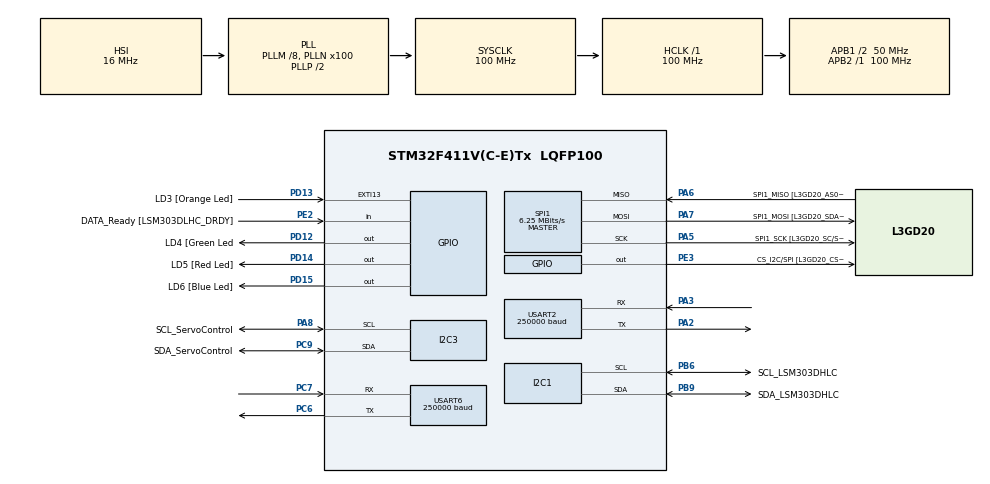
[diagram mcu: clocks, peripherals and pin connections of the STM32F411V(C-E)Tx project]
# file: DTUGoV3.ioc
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Dma.Request0=USART6_RX
Dma.Request1=USART6_TX
Dma.USART6_RX.0.Direction=DMA_PERIPH_TO_MEMORY
Dma.USART6_RX.0.FIFOMode=DMA_FIFOMODE_DISABLE
Dma.USART6_RX.0.Instance=DMA2_Stream1
Dma.USART6_RX.0.MemDataAlignment=DMA_MDATAALIGN_BYTE
Dma.USART6_RX.0.MemInc=DMA_MINC_ENABLE
Dma.USART6_RX.0.Mode=DMA_CIRCULAR
Dma.USART6_RX.0.PeriphDataAlignment=DMA_PDATAALIGN_BYTE
Dma.USART6_RX.0.PeriphInc=DMA_PINC_DISABLE
Dma.USART6_RX.0.Priority=DMA_PRIORITY_LOW
Dma.USART6_TX.1.Direction=DMA_MEMORY_TO_PERIPH
Dma.USART6_TX.1.FIFOMode=DMA_FIFOMODE_DISABLE
Dma.USART6_TX.1.Instance=DMA2_Stream6
Dma.USART6_TX.1.MemDataAlignment=DMA_MDATAALIGN_BYTE
Dma.USART6_TX.1.MemInc=DMA_MINC_ENABLE
Dma.USART6_TX.1.Mode=DMA_NORMAL
Dma.USART6_TX.1.PeriphDataAlignment=DMA_PDATAALIGN_BYTE
Dma.USART6_TX.1.PeriphInc=DMA_PINC_DISABLE
Dma.USART6_TX.1.Priority=DMA_PRIORITY_LOW
FREERTOS.Mutexes01=cmdMutex,Dynamic,NULL,Available;imuMutex,Dynamic,NULL,Available;batteryMutex,Dynamic,NULL,Available
FREERTOS.Tasks01=controlTask,48,256,StartControlTask,Default,NULL,Dynamic,NULL,NULL;imuTask,8,256,StartIMUTask,Default,NULL,Dynamic,NULL,NULL;rxCommTask,40,128,StartRxCommTask,Default,NULL,Dynamic,NULL,NULL;txCommTask,24,128,StartTxCommTask,Default,NULL,Dynamic,NULL,NULL;batteryTask,9,256,StartBatteryTask,Default,NULL,Dynamic,NULL,NULL
FREERTOS.configENABLE_FPU=1
I2C1.I2C_Mode=I2C_Fast
Mcu.Family=STM32F4
Mcu.Name=STM32F411V(C-E)Tx
Mcu.Package=LQFP100
NVIC.DMA2_Stream1_IRQn=true\:5\:0\:false\:false\:true\:true\:false\:true\:true
NVIC.DMA2_Stream6_IRQn=true\:5\:0\:false\:false\:true\:true\:false\:true\:true
NVIC.PriorityGroup=NVIC_PRIORITYGROUP_4
NVIC.TIM2_IRQn=true\:15\:0\:false\:false\:true\:false\:false\:true\:true
NVIC.TimeBase=TIM2_IRQn
NVIC.TimeBaseIP=TIM2
NVIC.USART6_IRQn=true\:5\:0\:false\:false\:true\:true\:true\:true\:true
PA13.Mode=Serial_Wire
PA13.Signal=SYS_JTMS-SWDIO
PA14.Mode=Serial_Wire
PA14.Signal=SYS_JTCK-SWCLK
PA2.Mode=Asynchronous
PA2.Signal=USART2_TX
PA3.Mode=Asynchronous
PA3.Signal=USART2_RX
PA5.GPIO_Label=SPI1_SCK [L3GD20_SC/SPC]
PA5.Mode=Full_Duplex_Master
PA5.Signal=SPI1_SCK
PA6.GPIO_Label=SPI1_MISO [L3GD20_AS0/SDO]
PA6.Mode=Full_Duplex_Master
PA6.Signal=SPI1_MISO
PA7.GPIO_Label=SPI1_MOSI [L3GD20_SDA/SDI/SDO]
PA7.Mode=Full_Duplex_Master
PA7.Signal=SPI1_MOSI
PA8.GPIO_Label=SCL_ServoControl
PA8.Mode=I2C
PA8.Signal=I2C3_SCL
PB6.GPIO_Label=SCL_LSM303DHLC
PB6.Mode=I2C
PB6.Signal=I2C1_SCL
PB9.GPIO_Label=SDA_LSM303DHLC
PB9.Mode=I2C
PB9.Signal=I2C1_SDA
PC6.Mode=Asynchronous
PC6.Signal=USART6_TX
PC7.Mode=Asynchronous
PC7.Signal=USART6_RX
PC9.GPIO_Label=SDA_ServoControl
PC9.Mode=I2C
PC9.Signal=I2C3_SDA
PD12.GPIO_Label=LD4 [Green Led
PD12.Signal=GPIO_Output
PD13.GPIO_Label=LD3 [Orange Led]
PD13.Signal=GPXTI13
PD14.GPIO_Label=LD5 [Red Led]
PD14.Signal=GPIO_Output
PD15.GPIO_Label=LD6 [Blue Led]
PD15.Signal=GPIO_Output
PE2.GPIO_Label=DATA_Ready [LSM303DLHC_DRDY]
PE2.Signal=GPIO_Input
PE3.GPIO_Label=CS_I2C/SPI [L3GD20_CS_I2C/SPI]
PE3.GPIO_Speed=GPIO_SPEED_FREQ_VERY_HIGH
PE3.PinState=GPIO_PIN_SET
PE3.Signal=GPIO_Output
PH0\ -\ OSC_IN.Mode=HSE-External-Oscillator
PH0\ -\ OSC_IN.Signal=RCC_OSC_IN
PH1\ -\ OSC_OUT.Mode=HSE-External-Oscillator
PH1\ -\ OSC_OUT.Signal=RCC_OSC_OUT
ProjectManager.HeapSize=0x200
ProjectManager.StackSize=0x400
ProjectManager.TargetToolchain=STM32CubeIDE
RCC.48MHZClocksFreq_Value=50000000
RCC.AHBFreq_Value=100000000
RCC.APB1CLKDivider=RCC_HCLK_DIV2
RCC.APB1Freq_Value=50000000
RCC.APB1TimFreq_Value=100000000
RCC.APB2Freq_Value=100000000
RCC.APB2TimFreq_Value=100000000
RCC.CortexFreq_Value=100000000
RCC.HCLKFreq_Value=100000000
RCC.HSE_VALUE=8000000
RCC.HSI_VALUE=16000000
RCC.LSE_VALUE=32768
RCC.PLLM=8
RCC.PLLN=100
RCC.SYSCLKFreq_VALUE=100000000
RCC.SYSCLKSource=RCC_SYSCLKSOURCE_PLLCLK
RCC.VCOOutputFreq_Value=200000000
SPI1.BaudRatePrescaler=SPI_BAUDRATEPRESCALER_16
SPI1.CLKPhase=SPI_PHASE_1EDGE
SPI1.CLKPolarity=SPI_POLARITY_LOW
SPI1.CalculateBaudRate=6.25 MBits/s
SPI1.Direction=SPI_DIRECTION_2LINES
SPI1.Mode=SPI_MODE_MASTER
SPI1.VirtualType=VM_MASTER
USART2.BaudRate=250000
USART2.VirtualMode=VM_ASYNC
USART6.BaudRate=250000
USART6.VirtualMode=VM_ASYNC
VP_FREERTOS_VS_CMSIS_V2.Mode=CMSIS_V2
VP_SYS_VS_tim2.Mode=TIM2
board=custom

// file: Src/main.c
/* USER CODE BEGIN Header */
/**
  ******************************************************************************
  * @file           : main.c
  * @brief          : Main program body
  ******************************************************************************
  * @attention
  *
  * Copyright (c) 2026 STMicroelectronics.
  * All rights reserved.
  *
  * This software is licensed under terms that can be found in the LICENSE file
  * in the root directory of this software component.
  * If no LICENSE file comes with this software, it is provided AS-IS.
  *
  ******************************************************************************
  */
/* USER CODE END Header */
#include "main.h"
#include "cmsis_os.h"

/* USER CODE BEGIN Includes */
#include "uart.h"
#include "freeRtosUser.h"
/* USER CODE END Includes */

I2C_HandleTypeDef hi2c1;
I2C_HandleTypeDef hi2c3;

SPI_HandleTypeDef hspi1;

UART_HandleTypeDef huart2;
UART_HandleTypeDef huart6;
DMA_HandleTypeDef hdma_usart6_rx;
DMA_HandleTypeDef hdma_usart6_tx;

void SystemClock_Config(void);
static void MX_GPIO_Init(void);
static void MX_DMA_Init(void);
static void MX_I2C1_Init(void);
static void MX_I2C3_Init(void);
static void MX_SPI1_Init(void);
static void MX_USART2_UART_Init(void);
static void MX_USART6_UART_Init(void);

int main(void)
{

  /* MCU Configuration--------------------------------------------------------*/

  /* Reset of all peripherals, Initializes the Flash interface and the Systick. */
  HAL_Init();

  /* Configure the system clock */
  SystemClock_Config();

  /* Initialize all configured peripherals */
  MX_GPIO_Init();
  MX_DMA_Init();
  MX_I2C1_Init();
  MX_I2C3_Init();
  MX_SPI1_Init();
  MX_USART2_UART_Init();
  MX_USART6_UART_Init();

  /* We should never get here as control is now taken by the scheduler */

  /* Infinite loop */
  /* USER CODE BEGIN WHILE */
  osKernelInitialize();
  MX_FREERTOS_Init();
  osKernelStart();

  while (1)
  {
    /* USER CODE END WHILE */

  }
}

void SystemClock_Config(void)
{
  RCC_OscInitTypeDef RCC_OscInitStruct = {0};
  RCC_ClkInitTypeDef RCC_ClkInitStruct = {0};

  /** Configure the main internal regulator output voltage
  */
  __HAL_RCC_PWR_CLK_ENABLE();
  __HAL_PWR_VOLTAGESCALING_CONFIG(PWR_REGULATOR_VOLTAGE_SCALE1);

  /** Initializes the RCC Oscillators according to the specified parameters
  * in the RCC_OscInitTypeDef structure.
  */
  RCC_OscInitStruct.OscillatorType = RCC_OSCILLATORTYPE_HSI;
  RCC_OscInitStruct.HSIState = RCC_HSI_ON;
  RCC_OscInitStruct.HSICalibrationValue = RCC_HSICALIBRATION_DEFAULT;
  RCC_OscInitStruct.PLL.PLLState = RCC_PLL_ON;
  RCC_OscInitStruct.PLL.PLLSource = RCC_PLLSOURCE_HSI;
  RCC_OscInitStruct.PLL.PLLM = 8;
  RCC_OscInitStruct.PLL.PLLN = 100;
  RCC_OscInitStruct.PLL.PLLP = RCC_PLLP_DIV2;
  RCC_OscInitStruct.PLL.PLLQ = 4;
  if (HAL_RCC_OscConfig(&RCC_OscInitStruct) != HAL_OK)
  {
    Error_Handler();
  }

  /** Initializes the CPU, AHB and APB buses clocks
  */
  RCC_ClkInitStruct.ClockType = RCC_CLOCKTYPE_HCLK|RCC_CLOCKTYPE_SYSCLK
                              |RCC_CLOCKTYPE_PCLK1|RCC_CLOCKTYPE_PCLK2;
  RCC_ClkInitStruct.SYSCLKSource = RCC_SYSCLKSOURCE_PLLCLK;
  RCC_ClkInitStruct.AHBCLKDivider = RCC_SYSCLK_DIV1;
  RCC_ClkInitStruct.APB1CLKDivider = RCC_HCLK_DIV2;
  RCC_ClkInitStruct.APB2CLKDivider = RCC_HCLK_DIV1;

  if (HAL_RCC_ClockConfig(&RCC_ClkInitStruct, FLASH_LATENCY_3) != HAL_OK)
  {
    Error_Handler();
  }
}

static void MX_I2C1_Init(void)
{

  hi2c1.Instance = I2C1;
  hi2c1.Init.ClockSpeed = 400000;
  hi2c1.Init.DutyCycle = I2C_DUTYCYCLE_2;
  hi2c1.Init.OwnAddress1 = 0;
  hi2c1.Init.AddressingMode = I2C_ADDRESSINGMODE_7BIT;
  hi2c1.Init.DualAddressMode = I2C_DUALADDRESS_DISABLE;
  hi2c1.Init.OwnAddress2 = 0;
  hi2c1.Init.GeneralCallMode = I2C_GENERALCALL_DISABLE;
  hi2c1.Init.NoStretchMode = I2C_NOSTRETCH_DISABLE;
  if (HAL_I2C_Init(&hi2c1) != HAL_OK)
  {
    Error_Handler();
  }

}

static void MX_I2C3_Init(void)
{

  hi2c3.Instance = I2C3;
  hi2c3.Init.ClockSpeed = 100000;
  hi2c3.Init.DutyCycle = I2C_DUTYCYCLE_2;
  hi2c3.Init.OwnAddress1 = 0;
  hi2c3.Init.AddressingMode = I2C_ADDRESSINGMODE_7BIT;
  hi2c3.Init.DualAddressMode = I2C_DUALADDRESS_DISABLE;
  hi2c3.Init.OwnAddress2 = 0;
  hi2c3.Init.GeneralCallMode = I2C_GENERALCALL_DISABLE;
  hi2c3.Init.NoStretchMode = I2C_NOSTRETCH_DISABLE;
  if (HAL_I2C_Init(&hi2c3) != HAL_OK)
  {
    Error_Handler();
  }

}

static void MX_SPI1_Init(void)
{

  /* SPI1 parameter configuration*/
  hspi1.Instance = SPI1;
  hspi1.Init.Mode = SPI_MODE_MASTER;
  hspi1.Init.Direction = SPI_DIRECTION_2LINES;
  hspi1.Init.DataSize = SPI_DATASIZE_8BIT;
  hspi1.Init.CLKPolarity = SPI_POLARITY_LOW;
  hspi1.Init.CLKPhase = SPI_PHASE_1EDGE;
  hspi1.Init.NSS = SPI_NSS_SOFT;
  hspi1.Init.BaudRatePrescaler = SPI_BAUDRATEPRESCALER_16;
  hspi1.Init.FirstBit = SPI_FIRSTBIT_MSB;
  hspi1.Init.TIMode = SPI_TIMODE_DISABLE;
  hspi1.Init.CRCCalculation = SPI_CRCCALCULATION_DISABLE;
  hspi1.Init.CRCPolynomial = 10;
  if (HAL_SPI_Init(&hspi1) != HAL_OK)
  {
    Error_Handler();
  }

}

static void MX_USART2_UART_Init(void)
{

  huart2.Instance = USART2;
  huart2.Init.BaudRate = 250000;
  huart2.Init.WordLength = UART_WORDLENGTH_8B;
  huart2.Init.StopBits = UART_STOPBITS_1;
  huart2.Init.Parity = UART_PARITY_NONE;
  huart2.Init.Mode = UART_MODE_TX_RX;
  huart2.Init.HwFlowCtl = UART_HWCONTROL_NONE;
  huart2.Init.OverSampling = UART_OVERSAMPLING_16;
  if (HAL_UART_Init(&huart2) != HAL_OK)
  {
    Error_Handler();
  }

}

static void MX_USART6_UART_Init(void)
{

  huart6.Instance = USART6;
  huart6.Init.BaudRate = 250000;
  huart6.Init.WordLength = UART_WORDLENGTH_8B;
  huart6.Init.StopBits = UART_STOPBITS_1;
  huart6.Init.Parity = UART_PARITY_NONE;
  huart6.Init.Mode = UART_MODE_TX_RX;
  huart6.Init.HwFlowCtl = UART_HWCONTROL_NONE;
  huart6.Init.OverSampling = UART_OVERSAMPLING_16;
  if (HAL_UART_Init(&huart6) != HAL_OK)
  {
    Error_Handler();
  }

}

static void MX_DMA_Init(void)
{

  /* DMA controller clock enable */
  __HAL_RCC_DMA2_CLK_ENABLE();

  /* DMA interrupt init */
  /* DMA2_Stream1_IRQn interrupt configuration */
  HAL_NVIC_SetPriority(DMA2_Stream1_IRQn, 5, 0);
  HAL_NVIC_EnableIRQ(DMA2_Stream1_IRQn);
  /* DMA2_Stream6_IRQn interrupt configuration */
  HAL_NVIC_SetPriority(DMA2_Stream6_IRQn, 5, 0);
  HAL_NVIC_EnableIRQ(DMA2_Stream6_IRQn);

}

static void MX_GPIO_Init(void)
{
  GPIO_InitTypeDef GPIO_InitStruct = {0};

  /* GPIO Ports Clock Enable */
  __HAL_RCC_GPIOE_CLK_ENABLE();
  __HAL_RCC_GPIOH_CLK_ENABLE();
  __HAL_RCC_GPIOA_CLK_ENABLE();
  __HAL_RCC_GPIOD_CLK_ENABLE();
  __HAL_RCC_GPIOC_CLK_ENABLE();
  __HAL_RCC_GPIOB_CLK_ENABLE();

  /*Configure GPIO pin Output Level */
  HAL_GPIO_WritePin(CS_I2C_SPI_GPIO_Port, CS_I2C_SPI_Pin, GPIO_PIN_SET);

  /*Configure GPIO pin Output Level */
  HAL_GPIO_WritePin(GPIOD, LD4__Green_Led_Pin|LD5_Pin|LD6_Pin, GPIO_PIN_RESET);

  /*Configure GPIO pin : DATA_Ready_Pin */
  GPIO_InitStruct.Pin = DATA_Ready_Pin;
  GPIO_InitStruct.Mode = GPIO_MODE_INPUT;
  GPIO_InitStruct.Pull = GPIO_NOPULL;
  HAL_GPIO_Init(DATA_Ready_GPIO_Port, &GPIO_InitStruct);

  /*Configure GPIO pin : CS_I2C_SPI_Pin */
  GPIO_InitStruct.Pin = CS_I2C_SPI_Pin;
  GPIO_InitStruct.Mode = GPIO_MODE_OUTPUT_PP;
  GPIO_InitStruct.Pull = GPIO_NOPULL;
  GPIO_InitStruct.Speed = GPIO_SPEED_FREQ_VERY_HIGH;
  HAL_GPIO_Init(CS_I2C_SPI_GPIO_Port, &GPIO_InitStruct);

  /*Configure GPIO pins : LD4__Green_Led_Pin LD5_Pin LD6_Pin */
  GPIO_InitStruct.Pin = LD4__Green_Led_Pin|LD5_Pin|LD6_Pin;
  GPIO_InitStruct.Mode = GPIO_MODE_OUTPUT_PP;
  GPIO_InitStruct.Pull = GPIO_NOPULL;
  GPIO_InitStruct.Speed = GPIO_SPEED_FREQ_LOW;
  HAL_GPIO_Init(GPIOD, &GPIO_InitStruct);

  /*Configure GPIO pin : LD3_Pin */
  GPIO_InitStruct.Pin = LD3_Pin;
  GPIO_InitStruct.Mode = GPIO_MODE_IT_RISING;
  GPIO_InitStruct.Pull = GPIO_NOPULL;
  HAL_GPIO_Init(LD3_GPIO_Port, &GPIO_InitStruct);

}

/* USER CODE BEGIN Header_StartControlTask */

/* USER CODE BEGIN Header_StartRxCommTask */

/* USER CODE BEGIN Header_StartTxCommTask */

/* USER CODE BEGIN Header_StartBatteryTask */

void HAL_TIM_PeriodElapsedCallback(TIM_HandleTypeDef *htim)
{
  if (htim->Instance == TIM2)
  {
    HAL_IncTick();
  }
}

void Error_Handler(void)
{
  __disable_irq();
  while (1)
  {
  }
}
